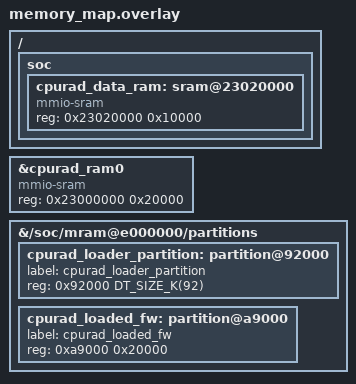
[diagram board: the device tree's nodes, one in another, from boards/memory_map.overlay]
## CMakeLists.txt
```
#
# Copyright (c) 2025 Nordic Semiconductor ASA
#
# SPDX-License-Identifier: LicenseRef-Nordic-5-Clause
#

cmake_minimum_required(VERSION 3.20.0)

find_package(Zephyr REQUIRED HINTS $ENV{ZEPHYR_BASE})

if(NOT SYSBUILD)
	message(FATAL_ERROR
		" This is a multi-image application that should be built using sysbuild.\n"
		" Add --sysbuild argument to west build command to prepare all the images.")
endif()

project(idle)

target_sources(app PRIVATE src/main.c)
target_include_directories(app PRIVATE ../../../../../samples/radio_loader/shared_magic)
```

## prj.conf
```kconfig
CONFIG_PRINTK=y
CONFIG_LOG=y

CONFIG_SOC_NRF54H20_CPURAD_ENABLE=y
```

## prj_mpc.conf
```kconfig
CONFIG_PRINTK=y
CONFIG_LOG=y

CONFIG_SOC_NRF54H20_CPURAD_ENABLE=y

CONFIG_RADIO_LOADER_MODE_MPC=y
```

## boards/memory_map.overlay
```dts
/*
 * Copyright (c) 2025 Nordic Semiconductor ASA
 *
 * SPDX-License-Identifier: LicenseRef-Nordic-5-Clause
 */

/*
 * Common memory map configuration for cpurad
 * Shared between remote firmware and radio_loader
 */

/{
	soc{
		cpurad_data_ram: sram@23020000 {
			compatible = "mmio-sram";
			reg = < 0x23020000 0x10000 >;
			#address-cells = < 0x1 >;
			#size-cells = < 0x1 >;
			ranges = < 0x0 0x23020000 0x10000 >;
		};
	};
};

&cpurad_ram0 {
	compatible = "mmio-sram";
	/delete-property/ reg;
	reg = < 0x23000000 0x20000 >;
	ranges = < 0x0 0x23000000 0x20000 >;
};

&{/soc/mram@e000000/partitions} {
	// Remove the old cpurad_slot0_partition definition
	/delete-node/ cpurad_slot0_partition;

	// Add new partition for loader
	cpurad_loader_partition: partition@92000 {
		label = "cpurad_loader_partition";
		reg = <0x92000 DT_SIZE_K(92)>;
	};

	// Add new partition for loaded firmware
	cpurad_loaded_fw: partition@a9000 {
		label = "cpurad_loaded_fw";
		// Size: 128KB (0x20000) for firmware image
		reg = <0xa9000 0x20000>;
	};
};
```

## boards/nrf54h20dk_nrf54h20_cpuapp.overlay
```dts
/*
 * Copyright (c) 2025 Nordic Semiconductor ASA
 *
 * SPDX-License-Identifier: LicenseRef-Nordic-5-Clause
 */

&cpuapp_data {
	reg = <0x2f000000 0x39000>;
};
```

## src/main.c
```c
/*
 * Copyright (c) 2025 Nordic Semiconductor ASA
 *
 * SPDX-License-Identifier: LicenseRef-Nordic-5-Clause
 */

#include <zephyr/kernel.h>
#include <zephyr/sys/printk.h>
#include <zephyr/logging/log.h>

#include "../../../../../samples/radio_loader/shared_magic/shared_magic.h"

LOG_MODULE_REGISTER(idle);

#define LOADED_FW_ADDR        		0x0e0a9000
#define LOADED_FW_SIZE        		0x20000

#define LOADED_FW_RAM_ADDR    		0x23000000
#define LOADED_FW_RAM_SIZE    		0x20000

void radio_fw_copy(void)
{
	printk("Waiting for the MPC to be configured.\n");
	/* Wait for the MPC to be configured. */
	shared_magic_wait_for_mpc_ready();
	printk("MPC is configured.\n");

	/* Copy the firmware to the TCM. */
	memcpy((void *)LOADED_FW_RAM_ADDR, (void *)LOADED_FW_ADDR, LOADED_FW_SIZE);
	printk("Copied the firmware to the TCM.\n");

	/* Set the magic to the boot ready magic. */
	shared_magic_set_boot_ready();
	printk("Magic set to the boot ready magic.\n");
}

int main(void)
{
	unsigned int cnt = 0;

	if (IS_ENABLED(CONFIG_RADIO_LOADER_MODE_MPC)) {
		radio_fw_copy();
	}

	LOG_INF("Multicore idle test on %s", CONFIG_BOARD_TARGET);
	while (1) {
		LOG_INF("Multicore idle test iteration %u", cnt++);
		k_msleep(2000);
	}

	return 0;
}
```
